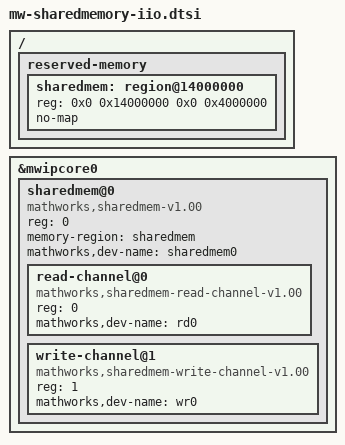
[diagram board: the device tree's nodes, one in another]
/ {
	reserved-memory {
		#address-cells = <2>;
		#size-cells = <2>;
		ranges;
		sharedmem: region@14000000 {
			reg = <0x0 0x14000000 0x0 0x4000000>;
			no-map;
		};
	};
};

&mwipcore0 {
	sharedmem@0 {
		reg = <0>;
		#address-cells = <1>;
		#size-cells = <0>;
		compatible = "mathworks,sharedmem-v1.00";
		memory-region = <&sharedmem>;
		mathworks,dev-name = "sharedmem0";

		read-channel@0 {
			reg = <0>;
			compatible = "mathworks,sharedmem-read-channel-v1.00";
			mathworks,dev-name = "rd0";
		};

		write-channel@1 {
			reg = <1>;
			compatible = "mathworks,sharedmem-write-channel-v1.00";
			mathworks,dev-name = "wr0";
		};
	};
};



